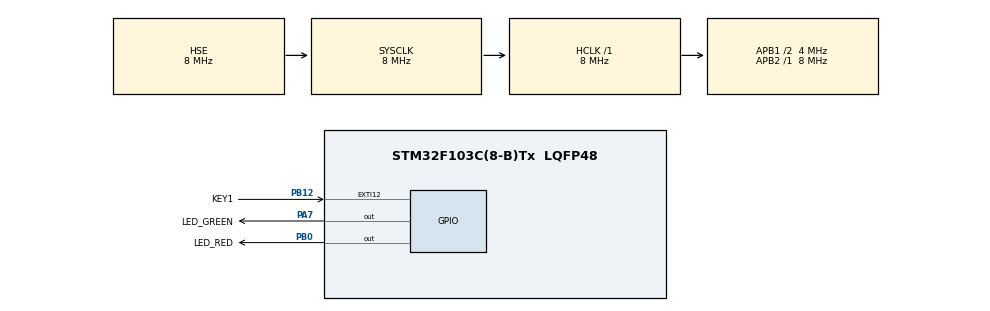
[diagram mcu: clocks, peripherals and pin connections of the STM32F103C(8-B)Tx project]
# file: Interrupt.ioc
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Mcu.Family=STM32F1
Mcu.Name=STM32F103C(8-B)Tx
Mcu.Package=LQFP48
NVIC.EXTI15_10_IRQn=true\:15\:0\:true\:false\:true\:true\:true\:true
NVIC.PriorityGroup=NVIC_PRIORITYGROUP_4
PA13.Mode=Serial_Wire
PA13.Signal=SYS_JTMS-SWDIO
PA14.Mode=Serial_Wire
PA14.Signal=SYS_JTCK-SWCLK
PA7.GPIO_Label=LED_GREEN
PA7.Signal=GPIO_Output
PB0.GPIO_Label=LED_RED
PB0.Signal=GPIO_Output
PB12.GPIO_Label=KEY1
PB12.GPIO_ModeDefaultEXTI=GPIO_MODE_IT_FALLING
PB12.Signal=GPXTI12
PD0-OSC_IN.Mode=HSE-External-Oscillator
PD0-OSC_IN.Signal=RCC_OSC_IN
PD1-OSC_OUT.Mode=HSE-External-Oscillator
PD1-OSC_OUT.Signal=RCC_OSC_OUT
ProjectManager.HeapSize=0x200
ProjectManager.StackSize=0x400
ProjectManager.TargetToolchain=STM32CubeIDE
RCC.AHBFreq_Value=8000000
RCC.APB1CLKDivider=RCC_HCLK_DIV2
RCC.APB1Freq_Value=4000000
RCC.APB1TimFreq_Value=8000000
RCC.APB2Freq_Value=8000000
RCC.APB2TimFreq_Value=8000000
RCC.HCLKFreq_Value=8000000
RCC.PLLMUL=RCC_PLL_MUL9
RCC.PLLSourceVirtual=RCC_PLLSOURCE_HSE
RCC.RCC_MCOSource=RCC_MCO1SOURCE_PLLCLK
RCC.SYSCLKFreq_VALUE=8000000
RCC.SYSCLKSource=RCC_SYSCLKSOURCE_HSE
RCC.USBFreq_Value=72000000
board=custom

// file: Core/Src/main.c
/* USER CODE BEGIN Header */
/**
  ******************************************************************************
  * @file           : main.c
  * @brief          : Main program body
  ******************************************************************************
  * @attention
  *
  * Copyright (c) 2025 STMicroelectronics.
  * All rights reserved.
  *
  * This software is licensed under terms that can be found in the LICENSE file
  * in the root directory of this software component.
  * If no LICENSE file comes with this software, it is provided AS-IS.
  *
  ******************************************************************************
  */
/* USER CODE END Header */
#include "main.h"

/* USER CODE BEGIN PV */
// LED控制函数
void RedLED_Toggle(void) {
    HAL_GPIO_TogglePin(LED_RED_GPIO_Port, LED_RED_Pin);
}

void GreenLED_Toggle(void) {
    HAL_GPIO_TogglePin(LED_GREEN_GPIO_Port, LED_GREEN_Pin);
}

void GreenLED_Off(void) {
    HAL_GPIO_WritePin(LED_GREEN_GPIO_Port, LED_GREEN_Pin, GPIO_PIN_RESET);
}

/* USER CODE END PV */

void SystemClock_Config(void);
static void GPIO_Init(void);

int main(void)
{

  /* MCU Configuration--------------------------------------------------------*/

  /* Reset of all peripherals, Initializes the Flash interface and the Systick. */
  HAL_Init();

  /* Configure the system clock */
  SystemClock_Config();

  /* Initialize all configured peripherals */
  GPIO_Init();
  /* USER CODE BEGIN 2 */
uint32_t lastRedToggleTime = 0; // 上次红灯翻转时间
uint32_t lastGreenEventTime = 0; // 上次绿灯事件时间
uint8_t greenState = 0; // 0 = 闪烁中，1 = 熄灭阶段
uint8_t greenFlashCount = 0; // 绿灯闪烁计数

  /* USER CODE END 2 */

  /* Infinite loop */
  /* USER CODE BEGIN WHILE */
while (1)
{
    uint32_t now = HAL_GetTick();

    // 红灯逻辑
    // 如果距离上次红灯反转超过500ms
    if (now - lastRedToggleTime >= 500) {
        RedLED_Toggle(); // 红灯电平反转
        lastRedToggleTime = now; // 记录红灯反转时间
    }

    // 绿灯逻辑
    // 如果绿灯处于闪烁状态
    if (greenState == 0) {
        // 如果距离上次绿灯反转超过200ms
        if (now - lastGreenEventTime >= 200) {
            lastGreenEventTime = now; // 记录绿灯反转时间
            GreenLED_Toggle(); // 绿灯电平反转
            greenFlashCount++; // 增加绿灯翻转次数
            if (greenFlashCount >= 10) { // 若超过闪烁5次(10次翻转)
                greenState = 1; // 设置小灯进入熄灭500ms阶段
                greenFlashCount = 0; // 清零绿灯翻转计数
                GreenLED_Off(); // 熄灭绿灯
                lastGreenEventTime = now; // 记录熄灭开始时间
            }
        }
    } else if (greenState == 1) { // 如果绿灯处于熄灭状态
        if (now - lastGreenEventTime >= 500) { // 若熄灭时间超过500ms
            greenState = 0; // 设置小灯进入闪烁状态
        }
    }
}
}
    /* USER CODE END WHILE */

void SystemClock_Config(void)
{
  RCC_OscInitTypeDef RCC_OscInitStruct = {0};
  RCC_ClkInitTypeDef RCC_ClkInitStruct = {0};

  /** Initializes the RCC Oscillators according to the specified parameters
  * in the RCC_OscInitTypeDef structure.
  */
  RCC_OscInitStruct.OscillatorType = RCC_OSCILLATORTYPE_HSE;
  RCC_OscInitStruct.HSEState = RCC_HSE_ON;
  RCC_OscInitStruct.PLL.PLLState = RCC_PLL_NONE;
  if (HAL_RCC_OscConfig(&RCC_OscInitStruct) != HAL_OK)
  {
    Error_Handler();
  }

  /** Initializes the CPU, AHB and APB buses clocks
  */
  RCC_ClkInitStruct.ClockType = RCC_CLOCKTYPE_HCLK|RCC_CLOCKTYPE_SYSCLK
                              |RCC_CLOCKTYPE_PCLK1|RCC_CLOCKTYPE_PCLK2;
  RCC_ClkInitStruct.SYSCLKSource = RCC_SYSCLKSOURCE_HSE;
  RCC_ClkInitStruct.AHBCLKDivider = RCC_SYSCLK_DIV1;
  RCC_ClkInitStruct.APB1CLKDivider = RCC_HCLK_DIV2;
  RCC_ClkInitStruct.APB2CLKDivider = RCC_HCLK_DIV1;

  if (HAL_RCC_ClockConfig(&RCC_ClkInitStruct, FLASH_LATENCY_0) != HAL_OK)
  {
    Error_Handler();
  }
}

static void GPIO_Init(void)
{
  GPIO_InitTypeDef GPIO_InitStruct = {0};

  /* GPIO Ports Clock Enable */
  __HAL_RCC_GPIOD_CLK_ENABLE();
  __HAL_RCC_GPIOA_CLK_ENABLE();
  __HAL_RCC_GPIOB_CLK_ENABLE();

  /*Configure GPIO pin Output Level */
  HAL_GPIO_WritePin(LED_GREEN_GPIO_Port, LED_GREEN_Pin, GPIO_PIN_RESET);

  /*Configure GPIO pin Output Level */
  HAL_GPIO_WritePin(LED_RED_GPIO_Port, LED_RED_Pin, GPIO_PIN_RESET);

  /*Configure GPIO pin : LED_GREEN_Pin */
  GPIO_InitStruct.Pin = LED_GREEN_Pin;
  GPIO_InitStruct.Mode = GPIO_MODE_OUTPUT_PP;
  GPIO_InitStruct.Pull = GPIO_NOPULL;
  GPIO_InitStruct.Speed = GPIO_SPEED_FREQ_LOW;
  HAL_GPIO_Init(LED_GREEN_GPIO_Port, &GPIO_InitStruct);

  /*Configure GPIO pin : LED_RED_Pin */
  GPIO_InitStruct.Pin = LED_RED_Pin;
  GPIO_InitStruct.Mode = GPIO_MODE_OUTPUT_PP;
  GPIO_InitStruct.Pull = GPIO_NOPULL;
  GPIO_InitStruct.Speed = GPIO_SPEED_FREQ_LOW;
  HAL_GPIO_Init(LED_RED_GPIO_Port, &GPIO_InitStruct);

  /*Configure GPIO pin : KEY1_Pin */
  GPIO_InitStruct.Pin = KEY1_Pin;
  GPIO_InitStruct.Mode = GPIO_MODE_IT_FALLING;
  GPIO_InitStruct.Pull = GPIO_NOPULL;
  HAL_GPIO_Init(KEY1_GPIO_Port, &GPIO_InitStruct);

  /* EXTI interrupt init*/
  HAL_NVIC_SetPriority(EXTI15_10_IRQn, 15, 0);
  HAL_NVIC_EnableIRQ(EXTI15_10_IRQn);

}

void Error_Handler(void)
{
  __disable_irq();
  while (1)
  {
  }
}
